# RasbperryPi register map
File version: 1
Registers are 32-bit, read-write, reset 0x0 unless marked. A register's access mark holds for its fields unless they carry their own. Offsets are from the block's base; [hi:lo] are bit positions; 'fields as' and 'values as' point back to an identical list.

## ACR — Derived from apb_arbiter_control.h apb_id: 0x61726272
Base 0x7E80A000
0x00 control 16-bit
  [15:0] data

## ASB — Derived from apb_async_bridge_ctrl.h apb_id: 0x62726467
Base 0x7E00A000
0x00 AXI_BRDG_VERSION 8-bit
  [7:0] data
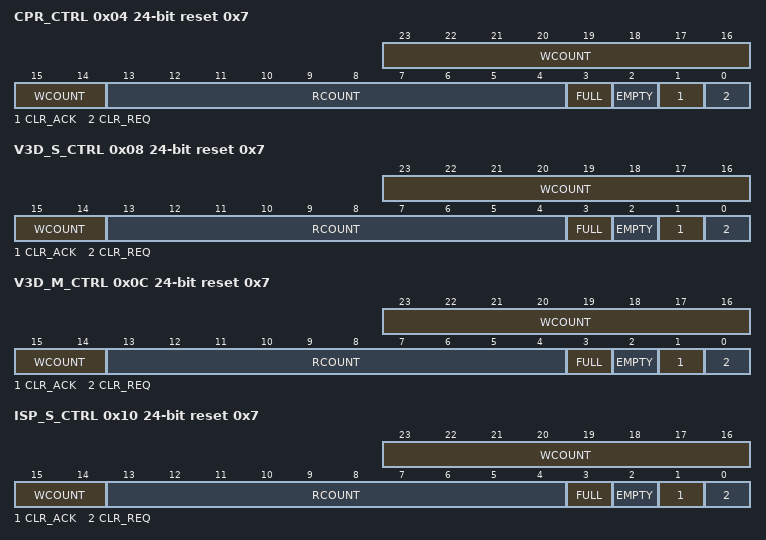
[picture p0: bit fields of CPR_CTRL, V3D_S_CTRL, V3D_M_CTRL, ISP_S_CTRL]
0x04 CPR_CTRL 24-bit reset 0x7
  [23:14] WCOUNT, [13:4] RCOUNT, [3] FULL, [2] EMPTY, [1] CLR_ACK, [0] CLR_REQ
0x08 V3D_S_CTRL 24-bit reset 0x7
  fields as CPR_CTRL
0x0C V3D_M_CTRL 24-bit reset 0x7
  fields as CPR_CTRL
0x10 ISP_S_CTRL 24-bit reset 0x7
  fields as CPR_CTRL
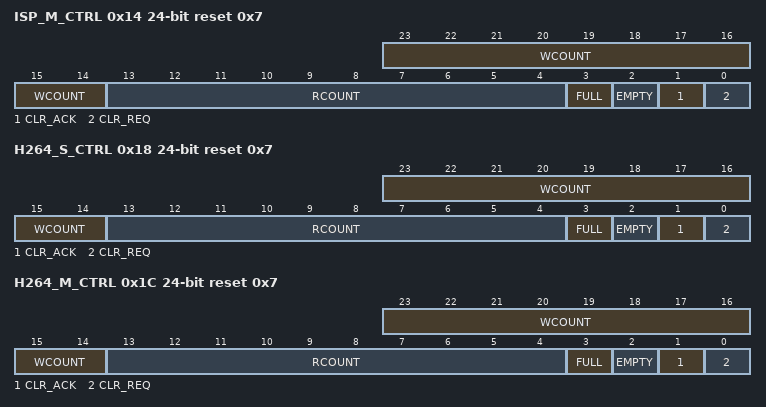
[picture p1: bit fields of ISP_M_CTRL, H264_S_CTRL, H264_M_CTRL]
0x14 ISP_M_CTRL 24-bit reset 0x7
  fields as CPR_CTRL
0x18 H264_S_CTRL 24-bit reset 0x7
  fields as CPR_CTRL
0x1C H264_M_CTRL 24-bit reset 0x7
  fields as CPR_CTRL

## AVE_IN — Derived from ave_in.h apb_id: 0x61766530
Base 0x7E910000
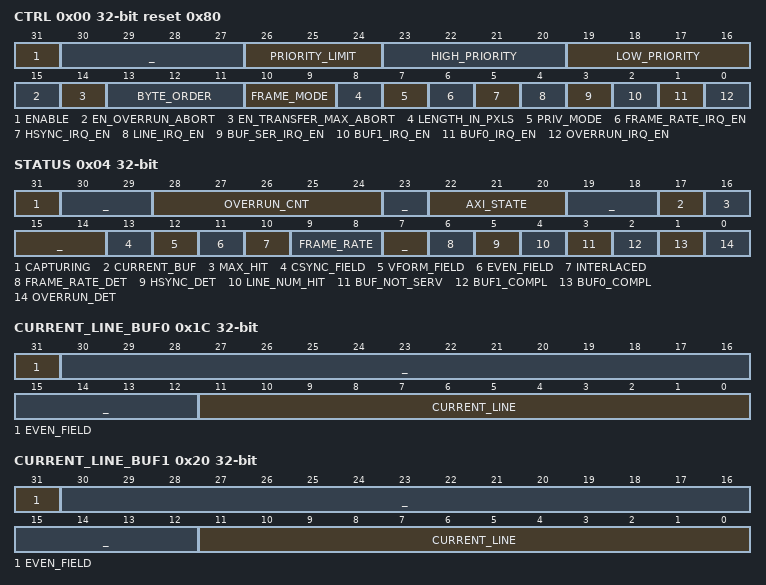
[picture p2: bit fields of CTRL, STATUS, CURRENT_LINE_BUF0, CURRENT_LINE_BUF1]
0x00 CTRL reset 0x80
  [31] ENABLE, [30:27] _, [26:24] PRIORITY_LIMIT, [23:20] HIGH_PRIORITY, [19:16] LOW_PRIORITY, [15] EN_OVERRUN_ABORT, [14] EN_TRANSFER_MAX_ABORT, [13:11] BYTE_ORDER, [10:9] FRAME_MODE, [8] LENGTH_IN_PXLS, [7] PRIV_MODE, [6] FRAME_RATE_IRQ_EN, [5] HSYNC_IRQ_EN, [4] LINE_IRQ_EN, [3] BUF_SER_IRQ_EN, [2] BUF1_IRQ_EN, [1] BUF0_IRQ_EN, [0] OVERRUN_IRQ_EN
0x04 STATUS
  [31] CAPTURING, [30:29] _, [28:24] OVERRUN_CNT, [23] _, [22:20] AXI_STATE, [19:18] _, [17] CURRENT_BUF, [16] MAX_HIT, [15:14] _, [13] CSYNC_FIELD, [12] VFORM_FIELD, [11] EVEN_FIELD, [10] INTERLACED, [9:8] FRAME_RATE, [7] _, [6] FRAME_RATE_DET, [5] HSYNC_DET, [4] LINE_NUM_HIT, [3] BUF_NOT_SERV, [2] BUF1_COMPL, [1] BUF0_COMPL, [0] OVERRUN_DET
0x08 BUF0_ADDRESS
  [31:0] BUF0_ADDR
0x0C BUF1_ADDRESS
  [31:0] BUF1_ADDR
0x10 MAX_TRANSFER
0x14 LINE_LENGTH 12-bit
0x18 CURRENT_ADDRESS
  [31:0] CUR_ADDR
0x1C CURRENT_LINE_BUF0
  [31] EVEN_FIELD, [30:12] _, [11:0] CURRENT_LINE
0x20 CURRENT_LINE_BUF1
  [31] EVEN_FIELD, [30:12] _, [11:0] CURRENT_LINE
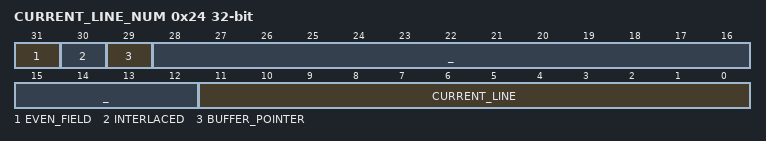
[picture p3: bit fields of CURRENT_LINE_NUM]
0x24 CURRENT_LINE_NUM
  [31] EVEN_FIELD, [30] INTERLACED, [29] BUFFER_POINTER, [28:12] _, [11:0] CURRENT_LINE
0x28 OVERRUN_ADDRESS
  [31:0] OVERRUN_ADDR
0x2C LINE_NUM_INT 12-bit
0x30 CALC_LINE_STEP 12-bit
0x34 OUTSTANDING_BUFF0 8-bit
  [7:0] data
0x38 OUTSTANDING_BUFF1 8-bit
  [7:0] data
0x3C CHAR_CTRL
  [31:0] data
0x40 SYNC_CTRL 8-bit
  [7:0] data
0x44 FRAME_NUM 12-bit
0x60 BLOCK_ID reset 0x30
  [31:0] data

## AVE_OUT — Derived from ave_out.h apb_id: 0x61766538
Base 0x7E240000
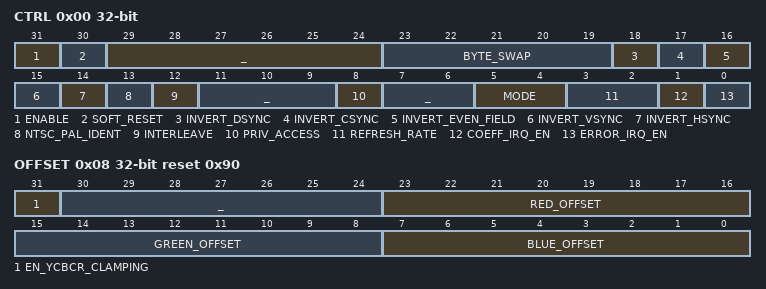
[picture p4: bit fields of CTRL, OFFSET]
0x00 CTRL
  [31] ENABLE, [30] SOFT_RESET, [29:24] _, [23:19] BYTE_SWAP, [18] INVERT_DSYNC, [17] INVERT_CSYNC, [16] INVERT_EVEN_FIELD, [15] INVERT_VSYNC, [14] INVERT_HSYNC, [13] NTSC_PAL_IDENT, [12] INTERLEAVE, [11:9] _, [8] PRIV_ACCESS, [7:6] _, [5:4] MODE, [3:2] REFRESH_RATE, [1] COEFF_IRQ_EN, [0] ERROR_IRQ_EN
0x04 STATUS 10-bit
  [9] VSYNC, [8] VBACK_PORCH, [7] VFRONT_PORCH, [6] HSYNC, [5] HBACK_PORCH, [4] HFRONT_PORCH, [3] _, [2] COEFF_ERROR, [1] PXL_OUTPUT_ERROR, [0] PXL_FORMAT_ERROR
0x08 OFFSET reset 0x90
  [31] EN_YCBCR_CLAMPING, [30:24] _, [23:16] RED_OFFSET, [15:8] GREEN_OFFSET, [7:0] BLUE_OFFSET
0x0C Y_COEFF 30-bit reset 0x3A
  [29:20] RED_COEFF, [19:10] GREEN_COEFF, [9:0] BLUE_COEFF
0x10 CB_COEFF 30-bit
  [29:20] RED_COEFF, [19:10] GREEN_COEFF, [9:0] BLUE_COEFF
0x14 CR_COEFF 30-bit reset 0xD6
  [29:20] RED_COEFF, [19:10] GREEN_COEFF, [9:0] BLUE_COEFF
0x60 BLOCK_ID reset 0x38
  [31:0] data

## DMA0 — Derived from axi_dma0.h
Base 0x7E007000
Same registers: DMA1 0x7E007100, DMA2 0x7E007200, DMA3 0x7E007300, DMA4 0x7E007400, DMA5 0x7E007500, DMA6 0x7E007600, DMA15 0x7EE05000
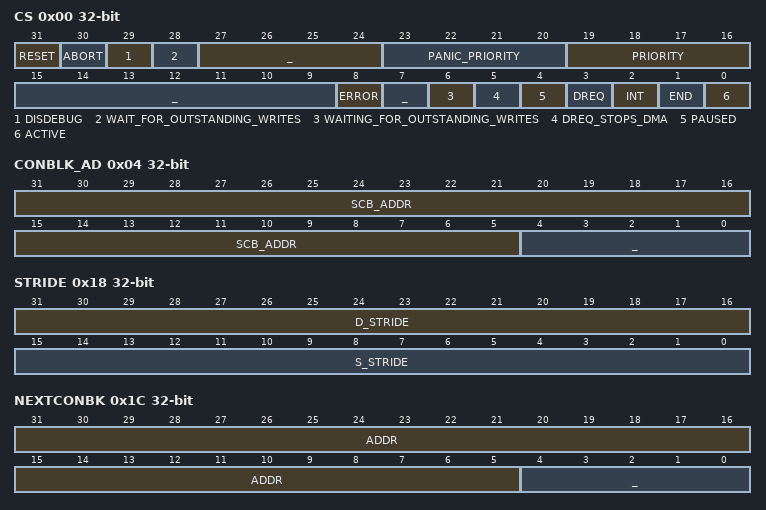
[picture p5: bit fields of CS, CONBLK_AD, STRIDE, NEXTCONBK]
0x00 CS
  [31] RESET, [30] ABORT, [29] DISDEBUG, [28] WAIT_FOR_OUTSTANDING_WRITES, [27:24] _, [23:20] PANIC_PRIORITY, [19:16] PRIORITY, [15:9] _, [8] ERROR, [7] _, [6] WAITING_FOR_OUTSTANDING_WRITES, [5] DREQ_STOPS_DMA, [4] PAUSED, [3] DREQ, [2] INT, [1] END, [0] ACTIVE
0x04 CONBLK_AD
  [31:5] SCB_ADDR, [4:0] _
0x08 TI 27-bit ro reset not defined
  [26] NO_WIDE_BURSTS, [25:21] WAITS, [20:16] PERMAP, [15:12] BURST_LENGTH, [11] SRC_IGNORE, [10] SRC_DREQ, [9] SRC_WIDTH, [8] SRC_INC, [7] DEST_IGNORE, [6] DEST_DREQ, [5] DEST_WIDTH, [4] DEST_INC, [3] WAIT_RESP, [2] _, [1] TDMODE, [0] INTEN
0x0C SOURCE_AD ro reset not defined
  [31:0] S_ADDR
0x10 DEST_AD ro reset not defined
  [31:0] D_ADDR
0x14 TXFR_LEN 30-bit ro reset not defined
  [29:16] YLENGTH, [15:0] XLENGTH
0x18 STRIDE ro reset not defined
  [31:16] D_STRIDE, [15:0] S_STRIDE
0x1C NEXTCONBK ro reset not defined
  [31:5] ADDR, [4:0] _
0x20 DEBUG 29-bit
  [28] LITE, [27:25] VERSION, [24:16] DMA_STATE, [15:8] DMA_ID, [7:4] OUTSTANDING_WRITES, [3] _, [2] READ_ERROR, [1] FIFO_ERROR, [0] READ_LAST_NOT_SET_ERROR

## DMA7 — Derived from axi_dma7.h
Base 0x7E007700
Registers as DMA0; these are added or differ:
0x14 TXFR_LEN 30-bit ro reset not defined
  [29:16] ylength, [15:0] xlength
0x1C NEXTCONBK ro reset not defined
  [31:0] data
0x20 DEBUG 28-bit
  [27:25] VERSION, [24:16] DMA_STATE, [15:8] DMA_ID, [7:4] OUTSTANDING_WRITES, [3] _, [2] READ_ERROR, [1] FIFO_ERROR, [0] READ_LAST_NOT_SET_ERROR

## DMA10 — Derived from axi_dma_lite10.h
Base 0x7E007A00
Same registers: DMA7 0x7E007700, DMA8 0x7E007800, DMA9 0x7E007900, DMA11 0x7E007B00, DMA12 0x7E007C00, DMA13 0x7E007D00, DMA14 0x7E007E00, DMA8 0x7EE05000
Registers as DMA0, without STRIDE; these are added or differ:
0x08 TI 26-bit ro reset not defined
  [25:21] WAITS, [20:16] PERMAP, [15:12] BURST_LENGTH, [11] SRC_IGNORE, [10] SRC_DREQ, [9] SRC_WIDTH, [8] SRC_INC, [7] DEST_IGNORE, [6] DEST_DREQ, [5] DEST_WIDTH, [4] DEST_INC, [3] WAIT_RESP, [2:1] _, [0] INTEN
0x14 TXFR_LEN 16-bit ro reset not defined
  [15:0] XLENGTH
